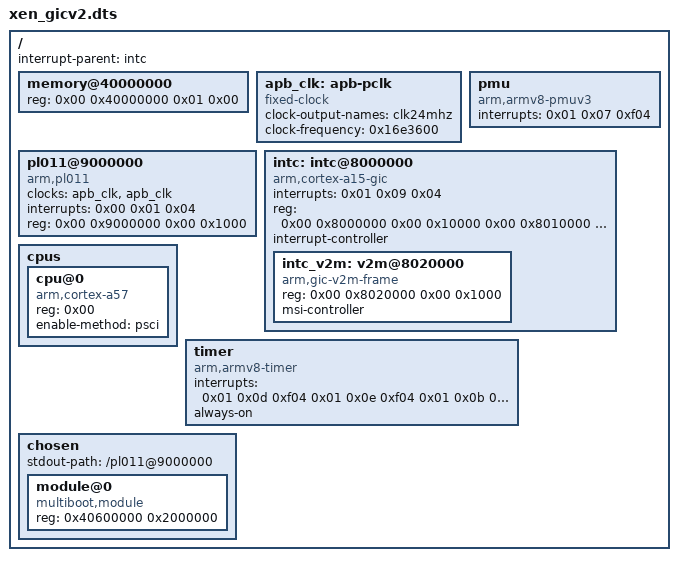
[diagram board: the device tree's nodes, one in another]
/dts-v1/;

/ {
	interrupt-parent = <&intc>;
	#size-cells = <0x02>;
	#address-cells = <0x02>;

	memory@40000000 {
		reg = <0x00 0x40000000 0x01 0x00>;
		device_type = "memory";
	};

	apb_clk: apb-pclk {
		clock-output-names = "clk24mhz";
		clock-frequency = <0x16e3600>;
		#clock-cells = <0x00>;
		compatible = "fixed-clock";
	};

	pl011@9000000 {
		clock-names = "uartclk", "apb_pclk";
		clocks = <&apb_clk &apb_clk>;
		interrupts = <0x00 0x01 0x04>;
		reg = <0x00 0x9000000 0x00 0x1000>;
		compatible = "arm,pl011", "arm,primecell";
	};

	pmu {
		interrupts = <0x01 0x07 0xf04>;
		compatible = "arm,armv8-pmuv3";
	};

	intc: intc@8000000 {
		interrupts = <0x01 0x09 0x04>;
		reg = <0x00 0x8000000 0x00 0x10000
		       0x00 0x8010000 0x00 0x10000
		       0x00 0x8030000 0x00 0x10000
		       0x00 0x8040000 0x00 0x10000>;
		compatible = "arm,cortex-a15-gic";
		ranges;
		#size-cells = <0x02>;
		#address-cells = <0x02>;
		interrupt-controller;
		#interrupt-cells = <0x03>;

		intc_v2m: v2m@8020000 {
			reg = <0x00 0x8020000 0x00 0x1000>;
			msi-controller;
			compatible = "arm,gic-v2m-frame";
		};
	};

	cpus {
		#size-cells = <0x00>;
		#address-cells = <0x01>;

		cpu@0 {
			reg = <0x00>;
			enable-method = "psci";
			compatible = "arm,cortex-a57";
			device_type = "cpu";
		};
	};

	timer {
		interrupts = <0x01 0x0d 0xf04 0x01 0x0e 0xf04 0x01 0x0b 0xf04 0x01 0x0a 0xf04>;
		always-on;
		compatible = "arm,armv8-timer", "arm,armv7-timer";
	};

	chosen {
		stdout-path = "/pl011@9000000";
		#address-cells = <1>;
		#size-cells = <1>;
		module@0 {
			compatible = "multiboot,module", "multiboot,kernel";
			reg = <0x40600000 0x2000000>;
		};
	};
};
